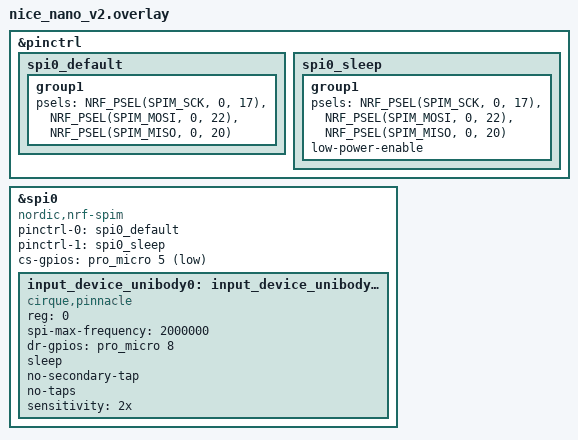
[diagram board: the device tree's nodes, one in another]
/**
 * Generated by Shield Wizard for ZMK
 * Applies to part "unibody" with controller "nice_nano_v2"
 */

// pin control for spi0
// - SCK on D2
// - MOSI on D4
// - MISO on D3
&pinctrl {
    /* configuration for spi0 device, default state */
    spi0_default: spi0_default {
        group1 {
            psels = <NRF_PSEL(SPIM_SCK, 0, 17)>,
                    <NRF_PSEL(SPIM_MOSI, 0, 22)>,
                    <NRF_PSEL(SPIM_MISO, 0, 20)>;
        };
    };
    /* configuration for spi0 device, sleep state */
    spi0_sleep: spi0_sleep {
        group1 {
            psels = <NRF_PSEL(SPIM_SCK, 0, 17)>,
                    <NRF_PSEL(SPIM_MOSI, 0, 22)>,
                    <NRF_PSEL(SPIM_MISO, 0, 20)>;
            low-power-enable;
        };
    };
};
&spi0 {
    compatible = "nordic,nrf-spim";
    status = "okay";
    pinctrl-0 = <&spi0_default>;
    pinctrl-1 = <&spi0_sleep>;
    pinctrl-names = "default", "sleep";
};

// devices on spi0

// CS pins for devices on spi0
&spi0 {
    cs-gpios = <&pro_micro 5 GPIO_ACTIVE_LOW>;
};

&spi0 {
    input_device_unibody0: input_device_unibody0@0 {
        status = "okay";
        compatible = "cirque,pinnacle";
        reg = <0>;
        spi-max-frequency = <2000000>;
        dr-gpios = <&pro_micro 8 (GPIO_ACTIVE_HIGH | GPIO_PULL_DOWN)>;
        sleep;
        no-secondary-tap;
        no-taps;
        sensitivity = "2x";
    };
};
